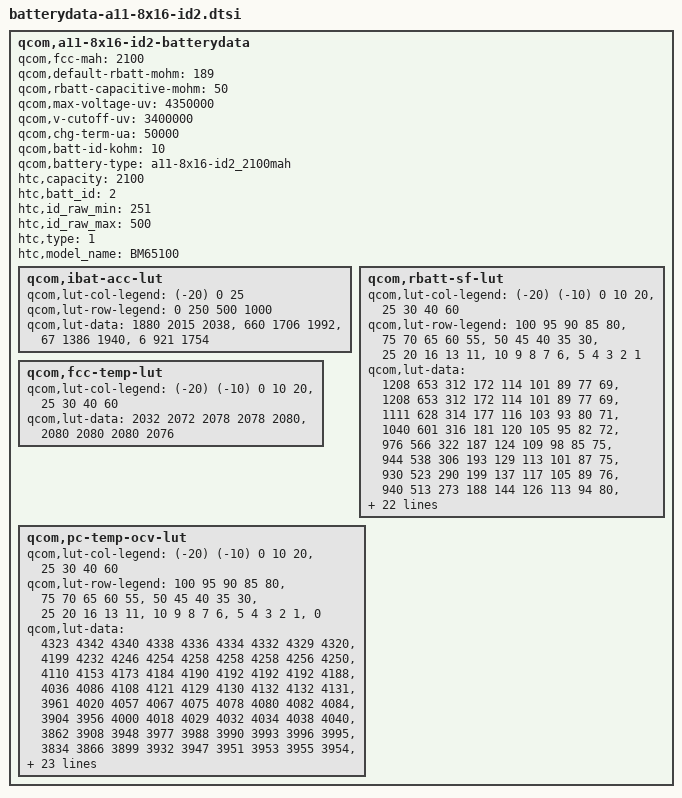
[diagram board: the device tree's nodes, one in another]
/* Copyright (c) 2013, The Linux Foundation. All rights reserved.
 *
 * This program is free software; you can redistribute it and/or modify
 * it under the terms of the GNU General Public License version 2 and
 * only version 2 as published by the Free Software Foundation.
 *
 * This program is distributed in the hope that it will be useful,
 * but WITHOUT ANY WARRANTY; without even the implied warranty of
 * MERCHANTABILITY or FITNESS FOR A PARTICULAR PURPOSE.  See the
 * GNU General Public License for more details.
 */

qcom,a11-8x16-id2-batterydata {
	qcom,fcc-mah = <2100>;
	qcom,default-rbatt-mohm = <189>;
	qcom,rbatt-capacitive-mohm = <50>;
	qcom,max-voltage-uv = <4350000>;
	qcom,v-cutoff-uv = <3400000>;
	qcom,chg-term-ua = <50000>;
	qcom,batt-id-kohm = <10>;
	qcom,battery-type = "a11-8x16-id2_2100mah";
	htc,capacity = <2100>;
	htc,batt_id = <2>;
	htc,id_raw_min = <251>;
	htc,id_raw_max = <500>;
	htc,type = <1>;
	htc,model_name = "BM65100";

	qcom,ibat-acc-lut {
		qcom,lut-col-legend = <(-20) 0 25>;
		qcom,lut-row-legend = <0 250 500 1000>;
		qcom,lut-data = <1880 2015 2038>,
				<660 1706 1992>,
				<67 1386 1940>,
				<6 921 1754>;
	};

	qcom,rbatt-sf-lut {
		qcom,lut-col-legend = <(-20) (-10) 0 10 20>,
				<25 30 40 60>;
		qcom,lut-row-legend = <100 95 90 85 80>,
				<75 70 65 60 55>,
				<50 45 40 35 30>,
				<25 20 16 13 11>,
				<10 9 8 7 6>,
				<5 4 3 2 1>;
		qcom,lut-data = <1208 653 312 172 114 101 89 77 69>,
				<1208 653 312 172 114 101 89 77 69>,
				<1111 628 314 177 116 103 93 80 71>,
				<1040 601 316 181 120 105 95 82 72>,
				<976 566 322 187 124 109 98 85 75>,
				<944 538 306 193 129 113 101 87 75>,
				<930 523 290 199 137 117 105 89 76>,
				<940 513 273 188 144 126 113 94 80>,
				<975 509 266 164 126 115 107 93 80>,
				<1023 528 263 157 111 98 90 79 71>,
				<1070 569 262 156 111 98 90 79 72>,
				<1116 620 277 154 112 99 92 83 74>,
				<1165 665 308 158 113 102 94 85 76>,
				<1220 707 353 173 116 103 95 85 78>,
				<1341 750 400 198 125 109 98 84 75>,
				<1578 798 452 225 134 113 101 84 73>,
				<1974 859 509 257 145 119 103 85 74>,
				<2478 921 559 286 154 125 106 87 75>,
				<3095 976 601 316 166 131 110 88 75>,
				<3734 1000 616 340 179 139 114 92 77>,
				<4129 1006 628 354 189 146 119 94 78>,
				<4586 1033 643 371 206 157 125 97 79>,
				<4997 1066 651 385 219 167 133 100 81>,
				<5592 1084 657 395 232 180 142 104 83>,
				<6219 1213 678 411 248 195 153 110 83>,
				<7916 1410 697 421 259 207 164 115 85>,
				<11756 1689 716 421 263 216 176 125 89>,
				<23511 2112 748 429 273 226 188 137 97>,
				<47022 2767 850 447 283 235 197 146 104>,
				<85117 3872 1196 576 316 253 211 162 151>;
	};

	qcom,fcc-temp-lut {
		qcom,lut-col-legend = <(-20) (-10) 0 10 20>,
				<25 30 40 60>;
		qcom,lut-data = <2032 2072 2078 2078 2080>,
				<2080 2080 2080 2076>;
	};

	qcom,pc-temp-ocv-lut {
		qcom,lut-col-legend = <(-20) (-10) 0 10 20>,
				<25 30 40 60>;
		qcom,lut-row-legend = <100 95 90 85 80>,
				<75 70 65 60 55>,
				<50 45 40 35 30>,
				<25 20 16 13 11>,
				<10 9 8 7 6>,
				<5 4 3 2 1>,
				<0>;
		qcom,lut-data = <4323 4342 4340 4338 4336 4334 4332 4329 4320>,
				<4199 4232 4246 4254 4258 4258 4258 4256 4250>,
				<4110 4153 4173 4184 4190 4192 4192 4192 4188>,
				<4036 4086 4108 4121 4129 4130 4132 4132 4131>,
				<3961 4020 4057 4067 4075 4078 4080 4082 4084>,
				<3904 3956 4000 4018 4029 4032 4034 4038 4040>,
				<3862 3908 3948 3977 3988 3990 3993 3996 3995>,
				<3834 3866 3899 3932 3947 3951 3953 3955 3954>,
				<3816 3830 3860 3880 3895 3900 3904 3906 3906>,
				<3798 3810 3828 3844 3852 3854 3856 3858 3859>,
				<3782 3796 3802 3816 3824 3826 3828 3830 3831>,
				<3763 3782 3788 3794 3802 3804 3806 3808 3808>,
				<3744 3768 3776 3780 3784 3786 3788 3789 3788>,
				<3721 3752 3768 3771 3772 3772 3773 3773 3772>,
				<3696 3732 3756 3762 3764 3764 3762 3758 3750>,
				<3667 3706 3737 3750 3750 3750 3748 3742 3728>,
				<3630 3672 3702 3720 3726 3724 3724 3718 3706>,
				<3590 3638 3668 3684 3692 3694 3693 3690 3680>,
				<3546 3608 3644 3658 3666 3668 3668 3668 3660>,
				<3504 3587 3626 3648 3656 3658 3660 3661 3655>,
				<3478 3576 3616 3642 3650 3654 3656 3657 3651>,
				<3449 3562 3604 3635 3646 3649 3652 3652 3647>,
				<3417 3547 3590 3627 3640 3644 3646 3646 3642>,
				<3380 3530 3576 3616 3633 3637 3638 3640 3633>,
				<3335 3504 3558 3601 3621 3626 3627 3627 3616>,
				<3278 3469 3529 3574 3596 3600 3601 3598 3582>,
				<3204 3425 3483 3524 3546 3552 3553 3549 3529>,
				<3112 3370 3418 3454 3476 3483 3486 3482 3460>,
				<3056 3298 3336 3362 3382 3390 3392 3388 3362>,
				<3027 3194 3216 3233 3246 3252 3252 3244 3210>,
				<3000 3000 3000 3000 3000 3000 3000 3000 3000>;
	};
};
